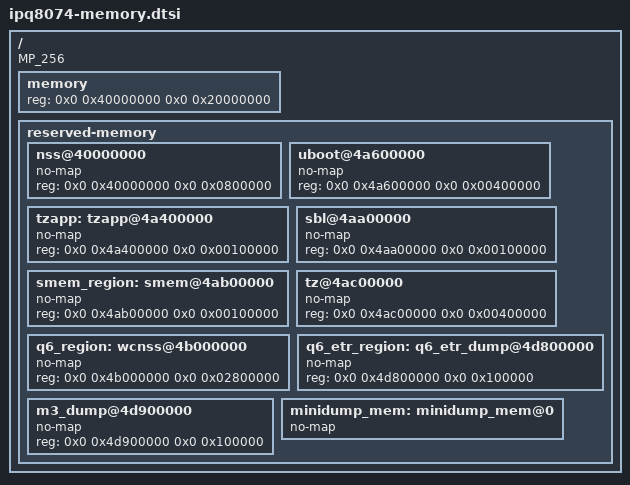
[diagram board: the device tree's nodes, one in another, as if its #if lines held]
/*
 * Copyright (c) 2016-2018, 2020, The Linux Foundation. All rights reserved.
 *
 * Permission to use, copy, modify, and/or distribute this software for any
 * purpose with or without fee is hereby granted, provided that the above
 * copyright notice and this permission notice appear in all copies.
 *
 * THE SOFTWARE IS PROVIDED "AS IS" AND THE AUTHOR DISCLAIMS ALL WARRANTIES
 * WITH REGARD TO THIS SOFTWARE INCLUDING ALL IMPLIED WARRANTIES OF
 * MERCHANTABILITY AND FITNESS. IN NO EVENT SHALL THE AUTHOR BE LIABLE FOR
 * ANY SPECIAL, DIRECT, INDIRECT, OR CONSEQUENTIAL DAMAGES OR ANY DAMAGES
 * WHATSOEVER RESULTING FROM LOSS OF USE, DATA OR PROFITS, WHETHER IN AN
 * ACTION OF CONTRACT, NEGLIGENCE OR OTHER TORTIOUS ACTION, ARISING OUT OF
 * OR IN CONNECTION WITH THE USE OR PERFORMANCE OF THIS SOFTWARE.
 */


/ {
	#ifdef __IPQ_MEM_PROFILE_256_MB__
	MP_256;
	#elif __IPQ_MEM_PROFILE_512_MB__
	MP_512;
	#endif

	memory {
		device_type = "memory";
		reg = <0x0 0x40000000 0x0 0x20000000>;
	};

	#ifdef __IPQ_MEM_PROFILE_256_MB__
	/*            256 MB Profile
	 * +=========+==============+========================+
	 * |        |              |                         |
	 * | Region | Start Offset |          Size           |
	 * |        |              |                         |
	 * +--------+--------------+-------------------------+
	 * |        |              |                         |
	 * |        |              |                         |
	 * |  NSS   |  0x40000000  |          8MB            |
	 * |        |              |                         |
	 * |        |              |                         |
	 * +--------+--------------+-------------------------+
	 * |        |              |                         |
	 * |        |              |                         |
	 * |        |              |                         |
	 * |        |              |                         |
	 * | Linux  |  0x40800000  | Depends on total memory |
	 * |        |              |                         |
	 * |        |              |                         |
	 * |        |              |                         |
	 * +--------+--------------+-------------------------+
	 * | TZ APP |  0x4A400000  |           1MB           |
	 * +--------+--------------+-------------------------+
	 * |        |              |                         |
	 * | uboot  |  0x4A600000  |           4MB           |
	 * |        |              |                         |
	 * +--------+--------------+-------------------------+
	 * |  SBL   |  0x4AA00000  |           1MB           |
	 * +--------+--------------+-------------------------+
	 * |  smem  |  0x4AB00000  |           1MB           |
	 * +--------+--------------+-------------------------+
	 * |        |              |                         |
	 * |   TZ   |  0x4AC00000  |           4MB           |
	 * |        |              |                         |
	 * +--------+--------------+-------------------------+
	 * |        |              |                         |
	 * |        |              |                         |
	 * |        |              |                         |
	 * |   Q6   |  0x4B000000  |          40MB           |
	 * |        |              |                         |
	 * |        |              |                         |
	 * |        |              |                         |
	 * +--------+--------------+-------------------------+
	 * |  QDSS  |  0x4D800000  |           1MB           |
	 * +--------+--------------+-------------------------+
	 * | M3 Dump|  0x4D900000  |           1MB           |
	 * +--------+--------------+-------------------------+
	 * |                                                 |
	 * |      Rest of the memory for Linux               |
	 * |                                                 |
	 * +=================================================+
	 */
	reserved-memory {
		#address-cells = <2>;
		#size-cells = <2>;
		ranges;

		nss@40000000 {
			no-map;
			reg = <0x0 0x40000000 0x0 0x0800000>;
		};

		uboot@4a600000 {
			no-map;
			reg = <0x0 0x4a600000 0x0 0x00400000>;
		};

		tzapp: tzapp@4a400000 {	/* TZAPPS */
			no-map;
			reg = <0x0 0x4a400000 0x0 0x00100000>;
		};

		sbl@4aa00000 {
			no-map;
			reg = <0x0 0x4aa00000 0x0 0x00100000>;
		};

		smem_region: smem@4ab00000 {
			no-map;
			reg = <0x0 0x4ab00000 0x0 0x00100000>;
		};

		tz@4ac00000 {	/* TZ */
			no-map;
			reg = <0x0 0x4ac00000 0x0 0x00400000>;
		};

		q6_region: wcnss@4b000000 {
			no-map;
			reg = <0x0 0x4b000000 0x0 0x02800000>;
		};

		q6_etr_region: q6_etr_dump@4d800000 {
			no-map;
			reg = <0x0 0x4d800000 0x0 0x100000>;
		};

		m3_dump@4d900000 {
			no-map;
			reg = <0x0 0x4d900000 0x0 0x100000>;
		};

		minidump_mem: minidump_mem@0 {
			no-map;
		};
	};
	#elif __IPQ_MEM_PROFILE_512_MB__
	/*                      512 MB Profile
	 * +=========+==============+========================+
	 * |        |              |                         |
	 * | Region | Start Offset |          Size           |
	 * |        |              |                         |
	 * +--------+--------------+-------------------------+
	 * |        |              |                         |
	 * |        |              |                         |
	 * |  NSS   |  0x40000000  |          16MB           |
	 * |        |              |                         |
	 * |        |              |                         |
	 * +--------+--------------+-------------------------+
	 * |        |              |                         |
	 * |        |              |                         |
	 * |        |              |                         |
	 * |        |              |                         |
	 * | Linux  |  0x41000000  | Depends on total memory |
	 * |        |              |                         |
	 * |        |              |                         |
	 * |        |              |                         |
	 * |        |              |                         |
	 * +--------+--------------+-------------------------+
	 * | TZ APP |  0x4A400000  |           1MB           |
	 * +--------+--------------+-------------------------+
	 * |        |              |                         |
	 * | uboot  |  0x4A600000  |           4MB           |
	 * |        |              |                         |
	 * +--------+--------------+-------------------------+
	 * |  SBL   |  0x4AA00000  |           1MB           |
	 * +--------+--------------+-------------------------+
	 * |  smem  |  0x4AB00000  |           1MB           |
	 * +--------+--------------+-------------------------+
	 * |        |              |                         |
	 * |   TZ   |  0x4AC00000  |           4MB           |
	 * |        |              |                         |
	 * +--------+--------------+-------------------------+
	 * |        |              |                         |
	 * |        |              |                         |
	 * |        |              |                         |
	 * |   Q6   |  0x4B000000  |          55MB           |
	 * |        |              |                         |
	 * |        |              |                         |
	 * |        |              |                         |
	 * +--------+--------------+-------------------------+
	 * |  QDSS  |  0x4E700000  |           1MB           |
	 * +--------+--------------+-------------------------+
	 * | M3 Dump|  0x4E800000  |           1MB           |
	 * +--------+--------------+-------------------------+
	 * |        |              |                         |
	 * |  Pine  |  0x4E900000  |          30MB           |
	 * |        |              |   (on HK10 RDPs only)   |
	 * +--------+--------------+-------------------------+
	 * |        |              |                         |
	 * |  Pine  |  0x50700000  |          30MB           |
	 * |        |              |   (on HK10 RDPs only)   |
	 * +--------+--------------+-------------------------+
	 * |        |              |                         |
	 * |  MHI0  |  0x52500000  |          16MB           |
	 * |        |              |   (on HK10 RDPs only)   |
	 * +--------+--------------+-------------------------+
	 * |        |              |                         |
	 * |  MHI1  |  0x53500000  |          16MB           |
	 * |        |              |   (on HK10 RDPs only)   |
	 * +--------+--------------+-------------------------+
	 * |                                                 |
	 * |      Rest of the memory for Linux               |
	 * |                                                 |
	 * +=================================================+
	 */
	reserved-memory {
		#address-cells = <2>;
		#size-cells = <2>;
		ranges;

		nss@40000000 {
			no-map;
			reg = <0x0 0x40000000 0x0 0x01000000>;
		};

		uboot@4a600000 {
			no-map;
			reg = <0x0 0x4a600000 0x0 0x00400000>;
		};

		tzapp: tzapp@4a400000 {	/* TZAPPS */
			no-map;
			reg = <0x0 0x4a400000 0x0 0x00100000>;
		};

		sbl@4aa00000 {
			no-map;
			reg = <0x0 0x4aa00000 0x0 0x00100000>;
		};

		smem_region: smem@4ab00000 {
			no-map;
			reg = <0x0 0x4ab00000 0x0 0x00100000>;
		};

		tz@4ac00000 {	/* TZ */
			no-map;
			reg = <0x0 0x4ac00000 0x0 0x00400000>;
		};

		q6_region: wcnss@4b000000 {
			no-map;
			reg = <0x0 0x4b000000 0x0 0x03700000>;
		};

		q6_etr_region: q6_etr_dump@4e700000 {
			no-map;
			reg = <0x0 0x4e700000 0x0 0x100000>;
		};

		m3_dump@4e800000 {
			no-map;
			reg = <0x0 0x4e800000 0x0 0x100000>;
		};

		minidump_mem: minidump_mem@0 {
			no-map;
		};
	};
	#else
	/*                   Default Profile
	 * +=========+==============+========================+
	 * |        |              |                         |
	 * | Region | Start Offset |          Size           |
	 * |        |              |                         |
	 * +--------+--------------+-------------------------+
	 * |        |              |                         |
	 * |        |              |                         |
	 * |  NSS   |  0x40000000  |          16MB           |
	 * |        |              |                         |
	 * |        |              |                         |
	 * +--------+--------------+-------------------------+
	 * |        |              |                         |
	 * |        |              |                         |
	 * |        |              |                         |
	 * |        |              |                         |
	 * | Linux  |  0x41000000  | Depends on total memory |
	 * |        |              |                         |
	 * |        |              |                         |
	 * |        |              |                         |
	 * +--------+--------------+-------------------------+
	 * | TZ APP |  0x4A400000  |           2MB           |
	 * +--------+--------------+-------------------------+
	 * |        |              |                         |
	 * | uboot  |  0x4A600000  |           4MB           |
	 * |        |              |                         |
	 * +--------+--------------+-------------------------+
	 * |  SBL   |  0x4AA00000  |           1MB           |
	 * +--------+--------------+-------------------------+
	 * |  smem  |  0x4AB00000  |           1MB           |
	 * +--------+--------------+-------------------------+
	 * |        |              |                         |
	 * |   TZ   |  0x4AC00000  |           4MB           |
	 * |        |              |                         |
	 * +--------+--------------+-------------------------+
	 * |        |              |                         |
	 * |        |              |                         |
	 * |        |              |                         |
	 * |   Q6   |  0x4B000000  |          95MB           |
	 * |        |              |                         |
	 * |        |              |                         |
	 * |        |              |                         |
	 * +--------+--------------+-------------------------+
	 * |  QDSS  |  0x50F00000  |           1MB           |
	 * +--------+--------------+-------------------------+
	 * | M3 Dump|  0x51000000  |           1MB           |
	 * +--------+--------------+-------------------------+
	 * |        |              |                         |
	 * |  Pine  |  0x51100000  |          45MB           |
	 * |        |              |   (on HK10 RDPs only)   |
	 * +--------+--------------+-------------------------+
	 * |        |              |                         |
	 * |  Pine  |  0x54800000  |          45MB           |
	 * |        |              |   (on HK10 RDPs only)   |
	 * +--------+--------------+-------------------------+
	 * |        |              |                         |
	 * |  MHI0  |  0x56B00000  |          24MB           |
	 * |        |              |   (on HK10 RDPs only)   |
	 * +--------+--------------+-------------------------+
	 * |        |              |                         |
	 * |  MHI1  |  0x58300000  |          24MB           |
	 * |        |              |   (on HK10 RDPs only)   |
	 * +--------+--------------+-------------------------+
	 * |                                                 |
	 * |      Rest of the memory for Linux               |
	 * |                                                 |
	 * +=================================================+
	 */

	reserved-memory {
		#address-cells = <2>;
		#size-cells = <2>;
		ranges;

		nss@40000000 {
			no-map;
			reg = <0x0 0x40000000 0x0 0x01000000>;
		};

		tzapp_data: tzapp_data@4a300000 {  /* TZAPP_DATA */
			compatible = "shared-dma-pool";
			no-map;
			reg = <0x0 0x4a300000 0x0 0x00100000>;
		};

		tzapp: tzapp@4a400000 {
			no-map;
			reg = <0x0 0x4a400000 0x0 0x00200000>;
		};

		uboot@4a600000 {
			no-map;
			reg = <0x0 0x4a600000 0x0 0x00400000>;
		};

		sbl@4aa00000 {
			no-map;
			reg = <0x0 0x4aa00000 0x0 0x00100000>;
		};

		smem_region: smem@4ab00000 {
			no-map;
			reg = <0x0 0x4ab00000 0x0 0x00100000>;
		};

		tz@4ac00000 {
			no-map;
			reg = <0x0 0x4ac00000 0x0 0x00400000>;
		};

		q6_region: wcnss@4b000000 {
			no-map;
			reg = <0x0 0x4b000000 0x0 0x05f00000>;
		};

		q6_etr_region: q6_etr_dump@50f00000 {
			no-map;
			reg = <0x0 0x50f00000 0x0 0x00100000>;
		};

		m3_dump@51000000 {
			no-map;
			reg = <0x0 0x51000000 0x0 0x100000>;
		};

		minidump_mem: minidump_mem@0 {
			no-map;
		};

	};
	#endif
};
